# ATSAMD11D14AS device description
Architecture: CORTEX-M0PLUS; Family: SAMD; Series: SAMD11
Registers are 32-bit, read-write, reset 0x0 unless marked. A register's access mark holds for its fields unless they carry their own. Offsets are from the block's base; [hi:lo] are bit positions; lines under a group give offsets from that group; {n}, {i} and the like mark numbered series; 'fields as' and 'values as' point back to an identical list; <NAME> marks a mode.

## TC — Basic Timer Counter
Instances: TC1 0x42001800, TC2 0x42001C00
Modes: COUNT8 when TC.CTRLA.MODE=1 (8-bit Counter Mode); COUNT16 when TC.CTRLA.MODE=0 (16-bit Counter Mode); COUNT32 when TC.CTRLA.MODE=2 (32-bit Counter Mode)
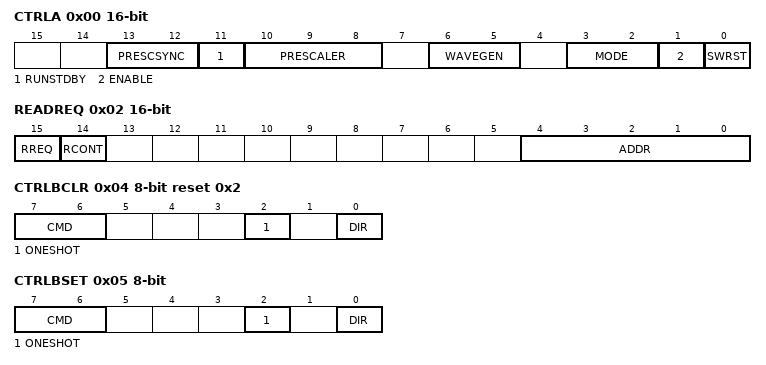
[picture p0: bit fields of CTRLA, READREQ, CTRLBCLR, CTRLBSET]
0x00 CTRLA 16-bit — Control A
  [13:12] PRESCSYNC — Prescaler and Counter Synchronization
    0=GCLK (Reload or reset the counter on next generic clock); 1=PRESC (Reload or reset the counter on next prescaler clock); 2=RESYNC (Reload or reset the counter on next generic clock. Reset the prescaler counter)
  [11] RUNSTDBY — Run in Standby
  [10:8] PRESCALER
    0=DIV1 (Prescaler: GCLK_TC); 1=DIV2 (Prescaler: GCLK_TC/2); 2=DIV4 (Prescaler: GCLK_TC/4); 3=DIV8 (Prescaler: GCLK_TC/8); 4=DIV16 (Prescaler: GCLK_TC/16); 5=DIV64 (Prescaler: GCLK_TC/64); 6=DIV256 (Prescaler: GCLK_TC/256); 7=DIV1024 (Prescaler: GCLK_TC/1024)
  [6:5] WAVEGEN — Waveform Generation Operation
    0=NFRQ; 1=MFRQ; 2=NPWM; 3=MPWM
  [3:2] MODE — TC Mode
    0=COUNT16 (Counter in 16-bit mode); 1=COUNT8 (Counter in 8-bit mode); 2=COUNT32 (Counter in 32-bit mode)
  [1] ENABLE
  [0] SWRST — Software Reset
0x02 READREQ 16-bit — Read Request
  [15] RREQ — Read Request
  [14] RCONT — Read Continuously
  [4:0] ADDR — Address
0x04 CTRLBCLR 8-bit reset 0x2 (atomic clear) — Control B Clear
  [7:6] CMD — Command
    0=NONE (No action); 1=RETRIGGER (Force a start, restart or retrigger); 2=STOP (Force a stop)
  [2] ONESHOT
  [0] DIR — Counter Direction
0x05 CTRLBSET 8-bit (atomic set) — Control B Set
  fields as CTRLBCLR
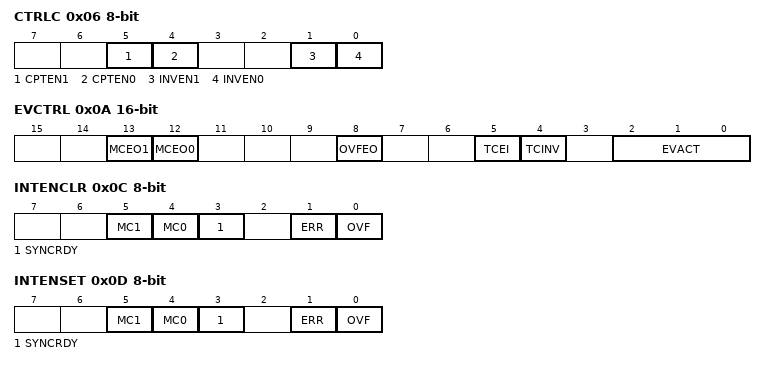
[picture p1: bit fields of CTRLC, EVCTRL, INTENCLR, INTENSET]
0x06 CTRLC 8-bit — Control C
  [5] CPTEN1 — Capture Channel 1 Enable
  [4] CPTEN0 — Capture Channel 0 Enable
  [1] INVEN1 — Output Waveform 1 Invert Enable
  [0] INVEN0 — Output Waveform 0 Invert Enable
0x08 DBGCTRL 8-bit — Debug Control
  [0] DBGRUN — Debug Run Mode
0x0A EVCTRL 16-bit — Event Control
  [13] MCEO1 — Match or Capture Channel 1 Event Output Enable
  [12] MCEO0 — Match or Capture Channel 0 Event Output Enable
  [8] OVFEO — Overflow/Underflow Event Output Enable
  [5] TCEI — TC Event Input
  [4] TCINV — TC Inverted Event Input
  [2:0] EVACT — Event Action
    0=OFF (Event action disabled); 1=RETRIGGER (Start, restart or retrigger TC on event); 2=COUNT (Count on event); 3=START (Start TC on event); 5=PPW (Period captured in CC0, pulse width in CC1); 6=PWP (Period captured in CC1, pulse width in CC0)
0x0C INTENCLR 8-bit (atomic clear) — Interrupt Enable Clear
  [5] MC1 — Match or Capture Channel 1 Interrupt Enable
  [4] MC0 — Match or Capture Channel 0 Interrupt Enable
  [3] SYNCRDY — Synchronization Ready Interrupt Enable
  [1] ERR — Error Interrupt Enable
  [0] OVF — Overflow Interrupt Enable
0x0D INTENSET 8-bit (atomic set) — Interrupt Enable Set
  fields as INTENCLR
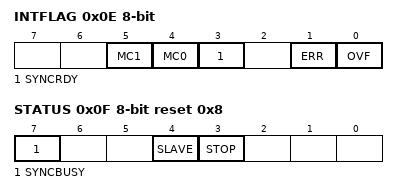
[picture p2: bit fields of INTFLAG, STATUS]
0x0E INTFLAG 8-bit (atomic clear) — Interrupt Flag Status and Clear
  [5] MC1 — Match or Capture Channel 1
  [4] MC0 — Match or Capture Channel 0
  [3] SYNCRDY — Synchronization Ready
  [1] ERR — Error
  [0] OVF — Overflow
0x0F STATUS 8-bit ro reset 0x8
  [7] SYNCBUSY — Synchronization Busy
  [4] SLAVE
  [3] STOP
0x10 COUNT <COUNT16> 16-bit — COUNT16 Counter Value
  [15:0] COUNT — Count Value
{0x18+2i} CC[{i}] (i=0..1) <COUNT16> 16-bit — COUNT16 Compare/Capture
  [15:0] CC — Compare/Capture Value
0x10 COUNT <COUNT32> — COUNT32 Counter Value
  [31:0] COUNT — Count Value
{0x18+4i} CC[{i}] (i=0..1) <COUNT32> — COUNT32 Compare/Capture
  [31:0] CC — Compare/Capture Value
0x10 COUNT <COUNT8> 8-bit — COUNT8 Counter Value
  [7:0] COUNT — Counter Value
0x14 PER <COUNT8> 8-bit reset 0xFF — COUNT8 Period Value
  [7:0] PER — Period Value
{0x18+i} CC[{i}] (i=0..1) <COUNT8> 8-bit — COUNT8 Compare/Capture
  [7:0] CC — Compare/Capture Value

## USB_DESCRIPTOR — Universal Serial Bus
Modes: DEVICE when USB.CTRLA.MODE=0 (USB is Device)
{0x0+0x10*i} DEVICE_DESC_BANK[{i}] (i=0..1) <DEVICE> group
  0x00 ADDR <DEVICE> reset not defined — DEVICE_DESC_BANK Endpoint Bank, Adress of Data Buffer
    [31:0] ADDR — Adress of data buffer
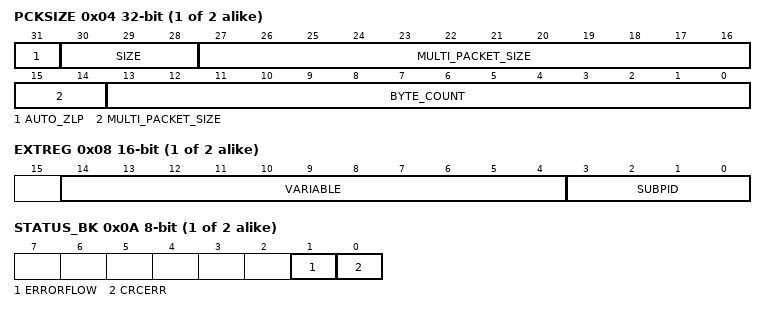
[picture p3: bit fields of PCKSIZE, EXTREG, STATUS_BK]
  0x04 PCKSIZE <DEVICE> reset not defined — DEVICE_DESC_BANK Endpoint Bank, Packet Size
    [31] AUTO_ZLP — Automatic Zero Length Packet
    [30:28] SIZE — Enpoint size
    [27:14] MULTI_PACKET_SIZE — Multi Packet In or Out size
    [13:0] BYTE_COUNT
  0x08 EXTREG <DEVICE> 16-bit reset not defined — DEVICE_DESC_BANK Endpoint Bank, Extended
    [14:4] VARIABLE — Variable field send with extended token
    [3:0] SUBPID — SUBPID field send with extended token
  0x0A STATUS_BK <DEVICE> 8-bit reset not defined — DEVICE_DESC_BANK Enpoint Bank, Status of Bank
    [1] ERRORFLOW — Error Flow Status
    [0] CRCERR — CRC Error Status

## Notices in the file
Copyright (c) 2018 Microchip Technology Inc.
SPDX-License-Identifier: Apache-2.0
Licensed under the Apache License, Version 2.0 (the "License");
you may not use this file except in compliance with the License.
You may obtain a copy of the License at
http://www.apache.org/licenses/LICENSE-2.0
Unless required by applicable law or agreed to in writing, software
distributed under the License is distributed on an "AS IS" BASIS,
WITHOUT WARRANTIES OR CONDITIONS OF ANY KIND, either express or implied.
See the License for the specific language governing permissions and
limitations under the License.
